# STM32H7S register map
File version: 1.3
CPU: CM7 r0p1, little endian, MPU, FPU, 4 interrupt priority bits
Registers are 32-bit, read-write, reset 0x0 unless marked. A register's access mark holds for its fields unless they carry their own. Offsets are from the block's base; [hi:lo] are bit positions; lines under a group give offsets from that group; {n}, {i} and the like mark numbered series.

## MCE1 — Memory cipher engine
Base 0x5200B800
Same registers: MCE2 0x5200BC00, MCE3 0x5200C000
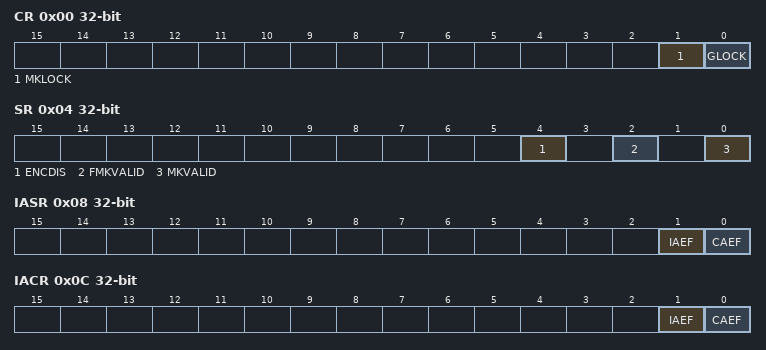
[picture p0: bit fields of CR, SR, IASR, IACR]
0x00 CR — MCE configuration register
  [1] MKLOCK — Master keys lock Lock the master key configurations until next reset. This bit is cleared by default and once set it cannot be reset until MCE reset. Effect of this bit depends on the number of master keys. See Section 35.3: MCE implementation for details.
  [0] GLOCK — Global lock Lock the configuration of most MCE registers until next reset. This bit is cleared by default and once set it cannot be reset until MCE reset.
0x04 SR ro — MCE status register
  [4] ENCDIS — encryption disabled This bit is set by hardware when the encryption feature is not functional. When ENCDIS is set application must reset MCE peripheral to be able to use the encryption feature again.
  [2] FMKVALID — Fast master key valid This bit is reserved when fast master key is not present in the MCE instance. See Section 35.3: MCE implementation for detail.
  [0] MKVALID — Master key valid
0x08 IASR ro — MCE illegal access status register
  [1] IAEF — Illegal access error flag This bit is set when an illegal access is detected on the system bus. More details on the error can be found in MCE_IAESR and MCE_IADDR registers. This bit is cleared by setting corresponding bit in MCE_IACR register.
  [0] CAEF — Configuration access error flag This bit is set when an illegal access to any MCE configuration register is detected. Bit is cleared by setting corresponding bit in MCE_IACR register. No additional details on the error is available.
0x0C IACR wo — MCE illegal access clear register
  [1] IAEF — Illegal access error flag clear Set this bit to clear IAEF bit in MCE_IASR register. Clearing IAEF bit permits to capture new error information in MCE_IAESR and MCE_IADDR registers. Note that clearing this bit does not clear RISAB_IADDR register.
  [0] CAEF — Configuration access error flag clear Set this bit to clear CAEF bit in MCE_IASR register.
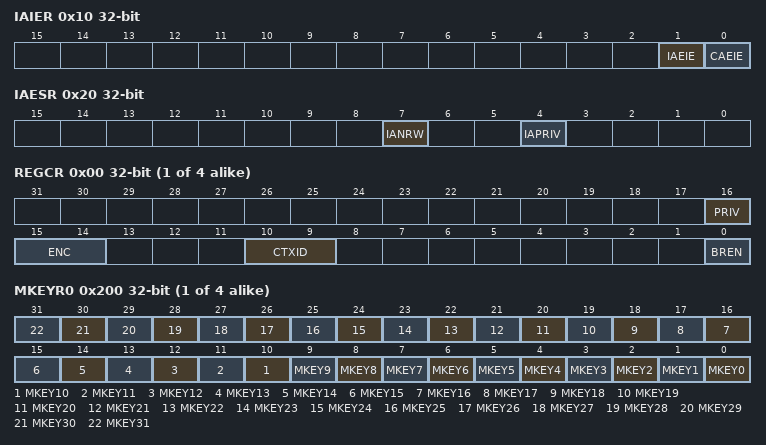
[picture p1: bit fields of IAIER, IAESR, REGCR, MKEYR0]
0x10 IAIER access per field — MCE illegal access interrupt enable register
  [1] IAEIE ro — Illegal access error interrupt enable
  [0] CAEIE rw — Configuration access error interrupt enable
0x1C PRIVCFGR — MCE privileged configuration register
  [0] PRIV — Privileged configuration
0x20 IAESR ro — MCE illegal access error status register
  [7] IANRW — Illegal access read/write When IAEF bit is set in MCE_IASR register IANRW bit captures the access type of the illegal access detected.
  [4] IAPRIV — Illegal access privilege When IAEF bit is set in MCE_IASR register IAPRIV bit captures the privileged state of the master that issued the illegal access detected on the AXI system bus.
0x24 IADDR ro — MCE illegal address register
  [31:0] IADD — Illegal address When IAEF bit is set in MCE_IASR register IADD bitfield captures the 32-bit bus address of the erroneous access. Additional information can be found in MCE_IAESR register.
{0x30+0x10*i} REG{i} (i=1..4) group — Region cluster
  0x00 REGCR — Region configuration register
    [16] PRIV — Privileged region This bit is taken into account only if BREN is set.
    [15:14] ENC — Encrypted region Those bits are taken into account only if BREN is set and if the corresponding encryption feature is available in the MCE instance (see Section 35.3: MCE implementation). Write to those bits is ignored if BREN is set.
    [10:9] CTXID — Context ID This bitfield defines the cryptographic context used by the cipher engine assigned to this region. If ENC=00 bitfield CTXID is ignored. If BREN is set write to this bitfield is ignored. If ENC=01 the key stored in MCE_CC1KEYR is used by the stream cipher. The nonce in MCE_CC1NRx registers and the version in MCE_CC1CR register are also used. If ENC=01 the key stored in MCE_CC2KEYR is used by the stream cipher. The nonce in MCE_CC2NRx registers and the version in MCE_CC2CR register are also used.
    [0] BREN — Base region enable BREN cannot be set if BADDRSTART > BADDREND.
  0x04 SADDR — Region start address register
    [31:12] BADDSTART — Region address start This bitfield defines the absolute start address of the region x on 4 kBytes boundary (inclusive). BREN cannot be set if BADDRSTART > BADDREND. When MCE determines the region, the first 12 bits (LSB) and the last 4 bits (MSB) in this register are ignored, and when this register is accessed in read the 4 MSB bits and the 12 LSB bits return zeros (reference value in MCE).
  0x08 EADDR reset 0xFFF — Region end address register
    [31:12] BADDEND — Region address end This bitfield defines the absolute end address of the region x on 4 kBytes boundary (inclusive). BREN cannot be set if BADDRSTART > BADDREND. When MCE determines the region, the first 12 bits (LSB) and the last 4 bits (MSB) in this register are ignored, and when this register is accessed in read the 4 MSB bits return zeros and the 12 LSB bits return ones (reference value in MCE).
  0x0C ATTR — Region attribute register
    [16] WREN — Write enable This bit is taken into account only if BREN is set.
{0x200+4i} MKEYR{i} (i=0..3) wo — MCE master key {i}
  [n] MKEY{n} (n=0..31) — Master key bit {n} This key is used by the MCE block cipher in normal, SCA resistant mode, if CTXID=0x0 in MCE_REGCR register.
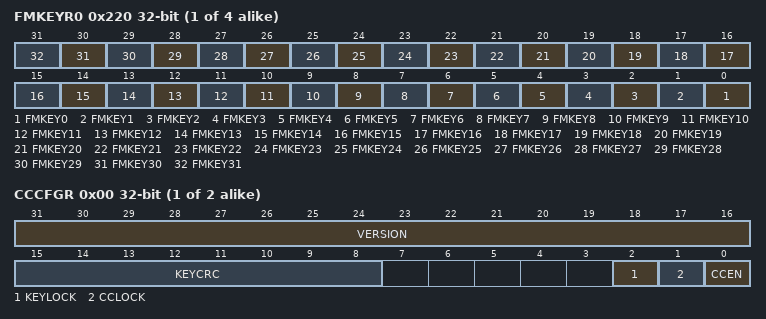
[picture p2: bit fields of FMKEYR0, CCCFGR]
{0x220+4i} FMKEYR{i} (i=0..3) wo — MCE fast master key {i}
  [n] FMKEY{n} (n=0..31) — Fast master key bit {n} This key is used by the MCE block cipher in fast mode, if CTXID=0x0 in MCE_REGCR register.
{0x210+0x30*i} CC{i} (i=1..2) group — Cipher context cluster
  0x00 CCCFGR access per field — MCE cipher context 1 configuration register
    [31:16] VERSION rw — Version This 16-bit bitfield must be correctly initialized before CCEN bit is set. Bitfield usage is defined in Section 35.4.6: MCE stream cipher encryption mode.
    [15:8] KEYCRC ro — Key CRC When KEYLOCK=0, KEYCRC information is automatically computed by hardware while loading the key of this region in this exact sequence: KEYR0 then KEYR1 then KEYR2 then finally KEYR3 (all written once). A new KEYCRC computation starts as soon as a new valid sequence is initiated. KEYCRC bitfield reads as zero until a valid sequence is completed (after it return the computed CRC value). When GLOCK=1, KEYCRC bitfield always return the computed CRC value until the next reset. CRC computation is an 8-bit checksum using the standard CRC-8-CCITT algorithm X8 + X2 + X + 1 (according the convention). Note: CRC information is updated, and the key is usable by MCE, only after the last bit of the key has been written. When GLOCK=0 any write to MCE_CCxKEYR registers clears KEYCRC in MCE_CCxCFGR, and makes the cipher context key un-usable (bypass mode is selected instead). To be able to use the key again application must perform this sequence: write to KEYR0 then KEYR1 then KEYR2 then finally KEYR3 (all written once). As KEYLOCK=1 all those writes are ignored, so the correct key is used instead.
    [2] KEYLOCK rw — Key lock Note: This bit is set once. If this bit is set, it can only be cleared to 0 if MCE is reset.
    [1] CCLOCK rw — Cipher context lock Note: This bit is set once. If this bit is set, it can only be cleared to 0 if MCE is reset. Setting this bit forces KEYLOCK bit to 1.
    [0] CCEN rw — Cipher context enable
  0x04 CCNR0 — MCE cipher context 1 nonce register 0
    [31:0] SCNONCE — Stream cipher nonce, bits [31:0] This register is used by stream cipher to compute keystream. It must be correctly initialize before CCEN bit is set in MCE_CCzCFGR register. Bitfield usage is defined in Section 35.4.6: MCE stream cipher encryption mode.
  0x08 CCNR1 — MCE cipher context 1 nonce register 1
    [31:0] SCNONCE — Stream cipher nonce, bits [63:32] Refer to the MCE_CCzNR0 register for description of the SCNONCE[63:0] bitfield.
  0x0C CCKEYR0 wo — MCE cipher context 1 key register 0
    [31:0] KEY — cipher key, bits [31:0] This register is used by the block or stream cipher of MCE when CTXID = z in encrypted region configuration register. KEY[127:0] must be correctly initialize before CCEN bit is set in MCE_CCzCFGR register.
  {0xC+4j} CCKEYR{j} wo (j=1..3) — MCE cipher context 1 key register {j}
    [31:0] KEY — cipher key, bits [{32j+31}:{32j}] Refer to the MCE_CCzKEYR0 register for description of the KEY[127:0] bitfield.
